# SAMA7G54D1G device description
Architecture: CORTEX-A7; Family: SAMA; Series: SAMA7G
Registers are 32-bit, read-write, reset 0x0 unless marked. A register's access mark holds for its fields unless they carry their own. Offsets are from the block's base; [hi:lo] are bit positions; {n}, {i} and the like mark numbered series.

## ACC — Analog Comparator Controller
Instances: ACC 0xE1600000
0x00 ACC_CR wo reset not defined — Control Register
  [0] SWRST — Software Reset
    0=No effect; 1=Resets the module
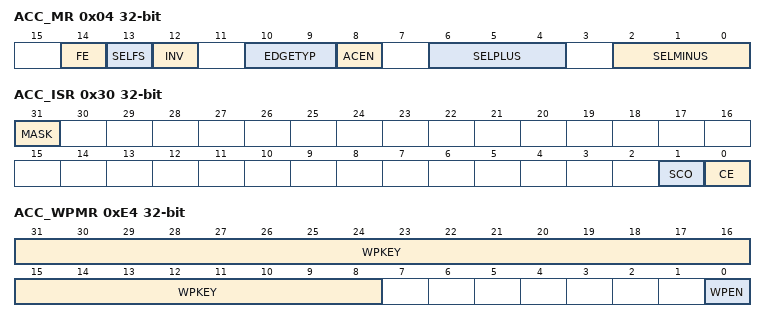
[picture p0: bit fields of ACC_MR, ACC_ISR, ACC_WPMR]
0x04 ACC_MR — Mode Register
  [14] FE — Fault Enable
    0=DIS (The FAULT output is tied to 0.); 1=EN (The FAULT output is driven by the signal defined by SELFS.)
  [13] SELFS — Selection Of Fault Source
    0=CE (The CE flag is used to drive the FAULT output.); 1=OUTPUT (The output of the analog comparator flag is used to drive the FAULT output.)
  [12] INV — Invert Comparator Output
    0=DIS (Analog comparator output is directly processed.); 1=EN (Analog comparator output is inverted prior to being processed.)
  [10:9] EDGETYP — Edge Type
    0=RISING (Only rising edge of comparator output); 1=FALLING (Falling edge of comparator output); 2=ANY (Any edge of comparator output)
  [8] ACEN — Analog Comparator Enable
    0=DIS (Analog comparator disabled.); 1=EN (Analog comparator enabled.)
  [6:4] SELPLUS — Selection For Plus Comparator Input
    {v}=ACC_INP{v} (Selects ACC_INP{v}) (v=0..3)
  [2:0] SELMINUS — Selection for Minus Comparator Input
    0=VBG (Selects VBG); 1=ACC_INN1 (Selects ACC_INN1); 2=ACC_INN2 (Selects ACC_INN2); 3=ACC_INN3 (Selects ACC_INN3)
0x24 ACC_IER wo reset not defined (atomic set of ACC_IMR) — Interrupt Enable Register
  [0] CE — Comparison Edge
    0=No effect; 1=Enables the interrupt when the selected edge (defined by EDGETYP) occurs
0x28 ACC_IDR wo reset not defined (atomic clear of ACC_IMR) — Interrupt Disable Register
  [0] CE — Comparison Edge
    0=No effect; 1=Disables the interrupt when the selected edge (defined by EDGETYP) occurs
0x2C ACC_IMR ro — Interrupt Mask Register
  [0] CE — Comparison Edge
    0=The interrupt is disabled; 1=The interrupt is enabled
0x30 ACC_ISR ro — Interrupt Status Register
  [31] MASK — Flag Mask
    0=The CE flag and SCO value are valid; 1=The CE flag and SCO value are invalid
  [1] SCO — Synchronized Comparator Output
  [0] CE — Comparison Edge (cleared on read)
    0=No edge occurred (defined by EDGETYP) on analog comparator output since the last read of ACC_ISR; 1=A selected edge (defined by EDGETYP) on analog comparator output occurred since the last read of ACC_ISR
0x94 ACC_ACR — Analog Control Register
  [0] MSEL — Masking Period Selection
    0=Masks AC output for 16 peripheral clock periods after any write access in ACC_MR or ACC_CR; 1=Masks AC output for 128 peripheral clock periods after any write access in ACC_MR or ACC_CR
0xE4 ACC_WPMR — Write Protection Mode Register
  [31:8] WPKEY — Write Protection Key
    0x414343=PASSWD (Writing any other value in this field aborts the write operation of the WPEN bit. Always reads as 0.)
  [0] WPEN — Write Protection Configuration Enable
    0=Disables the write protection if WPKEY corresponds to 0x414343 ("ACC" in ASCII); 1=Enables the write protection if WPKEY corresponds to 0x414343 ("ACC" in ASCII)
0xE8 ACC_WPSR ro — Write Protection Status Register
  [0] WPVS — Write Protection Violation Status
    0=No write protection violation has occurred since the last read of ACC_WPSR; 1=A write protection violation (WPEN = 1) has occurred since the last read of ACC_WPSR

## BSC — Boot Sequence Controller
Instances: BSC 0xE001D054
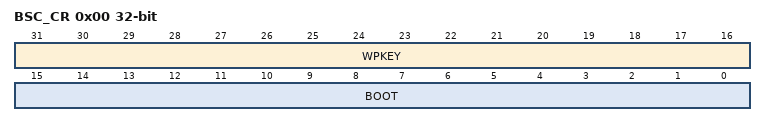
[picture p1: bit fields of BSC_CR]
0x00 BSC_CR reset not defined — Boot Sequence Controller Configuration Register
  [31:16] WPKEY — Write Protection Key (Write-only)
    0x6683=PASSWD (Writing any other value in this field aborts the write operation of the BOOT field. Always reads as 0.)
  [15:0] BOOT — Boot Media Sequence

## CHIPID — Chip Identifier
Instances: CHIPID 0xE0020000
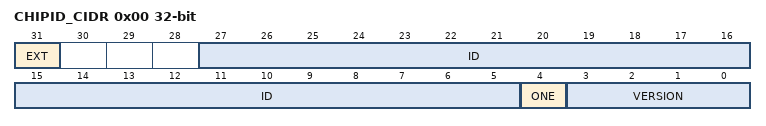
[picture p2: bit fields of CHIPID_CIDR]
0x00 CHIPID_CIDR ro reset not defined — Chip ID Register
  [31] EXT — Extension Flag
    0=Chip ID has a single register definition without extension; 1=An extended Chip ID exists
  [27:5] ID — Product ID
  [4] ONE — Must be at '1'
  [3:0] VERSION — Version of the Device
0x04 CHIPID_EXID ro reset not defined — Chip ID Extension Register
  [31:0] EXID — Chip ID Extension
